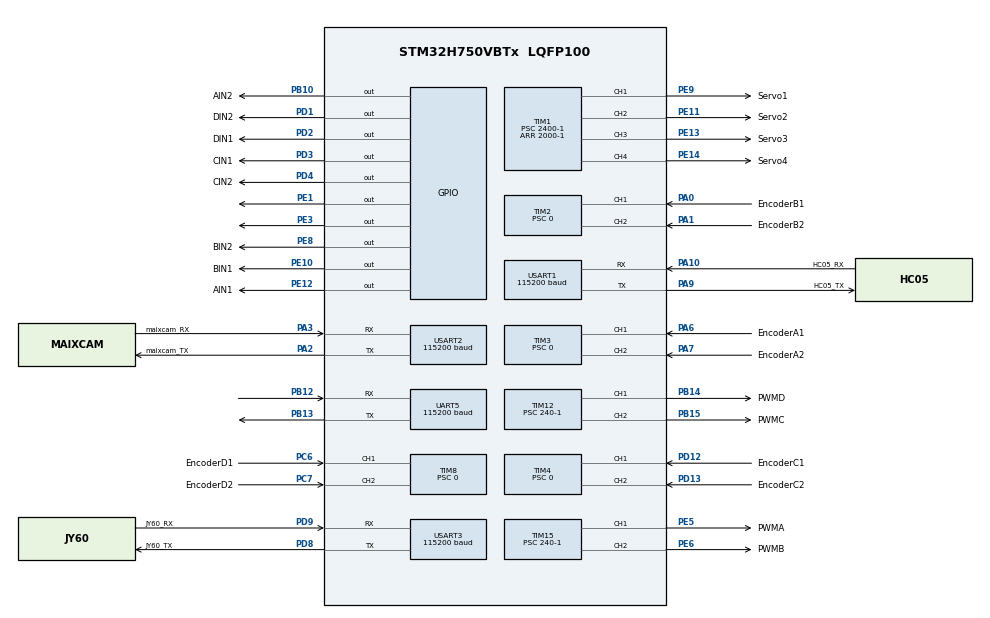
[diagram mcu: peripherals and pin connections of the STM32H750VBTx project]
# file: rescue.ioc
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CORTEX_M7.default_mode_Activation=1
Dma.Request0=USART2_RX
Dma.Request1=USART3_RX
Dma.Request2=UART5_RX
Dma.Request3=USART1_RX
Dma.Request4=USART1_TX
Dma.UART5_RX.2.Direction=DMA_PERIPH_TO_MEMORY
Dma.UART5_RX.2.EventEnable=DISABLE
Dma.UART5_RX.2.FIFOMode=DMA_FIFOMODE_DISABLE
Dma.UART5_RX.2.Instance=DMA1_Stream2
Dma.UART5_RX.2.MemDataAlignment=DMA_MDATAALIGN_BYTE
Dma.UART5_RX.2.MemInc=DMA_MINC_ENABLE
Dma.UART5_RX.2.Mode=DMA_NORMAL
Dma.UART5_RX.2.PeriphDataAlignment=DMA_PDATAALIGN_BYTE
Dma.UART5_RX.2.PeriphInc=DMA_PINC_DISABLE
Dma.UART5_RX.2.Polarity=HAL_DMAMUX_REQ_GEN_RISING
Dma.UART5_RX.2.Priority=DMA_PRIORITY_LOW
Dma.UART5_RX.2.RequestNumber=1
Dma.UART5_RX.2.SignalID=NONE
Dma.UART5_RX.2.SyncEnable=DISABLE
Dma.UART5_RX.2.SyncPolarity=HAL_DMAMUX_SYNC_NO_EVENT
Dma.UART5_RX.2.SyncRequestNumber=1
Dma.UART5_RX.2.SyncSignalID=NONE
Dma.USART1_RX.3.Direction=DMA_PERIPH_TO_MEMORY
Dma.USART1_RX.3.EventEnable=DISABLE
Dma.USART1_RX.3.FIFOMode=DMA_FIFOMODE_DISABLE
Dma.USART1_RX.3.Instance=DMA1_Stream3
Dma.USART1_RX.3.MemDataAlignment=DMA_MDATAALIGN_BYTE
Dma.USART1_RX.3.MemInc=DMA_MINC_ENABLE
Dma.USART1_RX.3.Mode=DMA_NORMAL
Dma.USART1_RX.3.PeriphDataAlignment=DMA_PDATAALIGN_BYTE
Dma.USART1_RX.3.PeriphInc=DMA_PINC_DISABLE
Dma.USART1_RX.3.Polarity=HAL_DMAMUX_REQ_GEN_RISING
Dma.USART1_RX.3.Priority=DMA_PRIORITY_LOW
Dma.USART1_RX.3.RequestNumber=1
Dma.USART1_RX.3.SignalID=NONE
Dma.USART1_RX.3.SyncEnable=DISABLE
Dma.USART1_RX.3.SyncPolarity=HAL_DMAMUX_SYNC_NO_EVENT
Dma.USART1_RX.3.SyncRequestNumber=1
Dma.USART1_RX.3.SyncSignalID=NONE
Dma.USART1_TX.4.Direction=DMA_MEMORY_TO_PERIPH
Dma.USART1_TX.4.EventEnable=DISABLE
Dma.USART1_TX.4.FIFOMode=DMA_FIFOMODE_DISABLE
Dma.USART1_TX.4.Instance=DMA1_Stream4
Dma.USART1_TX.4.MemDataAlignment=DMA_MDATAALIGN_BYTE
Dma.USART1_TX.4.MemInc=DMA_MINC_ENABLE
Dma.USART1_TX.4.Mode=DMA_NORMAL
Dma.USART1_TX.4.PeriphDataAlignment=DMA_PDATAALIGN_BYTE
Dma.USART1_TX.4.PeriphInc=DMA_PINC_DISABLE
Dma.USART1_TX.4.Polarity=HAL_DMAMUX_REQ_GEN_RISING
Dma.USART1_TX.4.Priority=DMA_PRIORITY_LOW
Dma.USART1_TX.4.RequestNumber=1
Dma.USART1_TX.4.SignalID=NONE
Dma.USART1_TX.4.SyncEnable=DISABLE
Dma.USART1_TX.4.SyncPolarity=HAL_DMAMUX_SYNC_NO_EVENT
Dma.USART1_TX.4.SyncRequestNumber=1
Dma.USART1_TX.4.SyncSignalID=NONE
Dma.USART2_RX.0.Direction=DMA_PERIPH_TO_MEMORY
Dma.USART2_RX.0.EventEnable=DISABLE
Dma.USART2_RX.0.FIFOMode=DMA_FIFOMODE_DISABLE
Dma.USART2_RX.0.Instance=DMA1_Stream0
Dma.USART2_RX.0.MemDataAlignment=DMA_MDATAALIGN_BYTE
Dma.USART2_RX.0.MemInc=DMA_MINC_ENABLE
Dma.USART2_RX.0.Mode=DMA_NORMAL
Dma.USART2_RX.0.PeriphDataAlignment=DMA_PDATAALIGN_BYTE
Dma.USART2_RX.0.PeriphInc=DMA_PINC_DISABLE
Dma.USART2_RX.0.Polarity=HAL_DMAMUX_REQ_GEN_RISING
Dma.USART2_RX.0.Priority=DMA_PRIORITY_LOW
Dma.USART2_RX.0.RequestNumber=1
Dma.USART2_RX.0.SignalID=NONE
Dma.USART2_RX.0.SyncEnable=DISABLE
Dma.USART2_RX.0.SyncPolarity=HAL_DMAMUX_SYNC_NO_EVENT
Dma.USART2_RX.0.SyncRequestNumber=1
Dma.USART2_RX.0.SyncSignalID=NONE
Dma.USART3_RX.1.Direction=DMA_PERIPH_TO_MEMORY
Dma.USART3_RX.1.EventEnable=DISABLE
Dma.USART3_RX.1.FIFOMode=DMA_FIFOMODE_DISABLE
Dma.USART3_RX.1.Instance=DMA1_Stream1
Dma.USART3_RX.1.MemDataAlignment=DMA_MDATAALIGN_BYTE
Dma.USART3_RX.1.MemInc=DMA_MINC_ENABLE
Dma.USART3_RX.1.Mode=DMA_NORMAL
Dma.USART3_RX.1.PeriphDataAlignment=DMA_PDATAALIGN_BYTE
Dma.USART3_RX.1.PeriphInc=DMA_PINC_DISABLE
Dma.USART3_RX.1.Polarity=HAL_DMAMUX_REQ_GEN_RISING
Dma.USART3_RX.1.Priority=DMA_PRIORITY_LOW
Dma.USART3_RX.1.RequestNumber=1
Dma.USART3_RX.1.SignalID=NONE
Dma.USART3_RX.1.SyncEnable=DISABLE
Dma.USART3_RX.1.SyncPolarity=HAL_DMAMUX_SYNC_NO_EVENT
Dma.USART3_RX.1.SyncRequestNumber=1
Dma.USART3_RX.1.SyncSignalID=NONE
FREERTOS.Tasks01=defaultTask,24,128,StartDefaultTask,Default,NULL,Dynamic,NULL,NULL
FREERTOS.configUSE_NEWLIB_REENTRANT=1
Mcu.Family=STM32H7
Mcu.Name=STM32H750VBTx
Mcu.Package=LQFP100
NVIC.DMA1_Stream0_IRQn=true\:5\:0\:false\:false\:true\:true\:false\:true\:true
NVIC.DMA1_Stream1_IRQn=true\:5\:0\:false\:false\:true\:true\:false\:true\:true
NVIC.DMA1_Stream2_IRQn=true\:5\:0\:false\:false\:true\:true\:false\:true\:true
NVIC.DMA1_Stream3_IRQn=true\:5\:0\:false\:false\:true\:true\:false\:true\:true
NVIC.DMA1_Stream4_IRQn=true\:5\:0\:false\:false\:true\:true\:false\:true\:true
NVIC.PriorityGroup=NVIC_PRIORITYGROUP_4
NVIC.TIM17_IRQn=true\:15\:0\:false\:false\:true\:false\:false\:true\:true
NVIC.TIM5_IRQn=true\:7\:0\:true\:false\:true\:true\:true\:true\:true
NVIC.TIM6_DAC_IRQn=true\:8\:0\:true\:false\:true\:true\:true\:true\:true
NVIC.TimeBase=TIM17_IRQn
NVIC.TimeBaseIP=TIM17
NVIC.UART5_IRQn=true\:7\:0\:true\:false\:true\:true\:true\:true\:true
NVIC.USART1_IRQn=true\:7\:0\:true\:false\:true\:true\:true\:true\:true
NVIC.USART2_IRQn=true\:7\:0\:true\:false\:true\:true\:true\:true\:true
NVIC.USART3_IRQn=true\:7\:0\:true\:false\:true\:true\:true\:true\:true
PA0.GPIO_Label=EncoderB1
PA0.GPIO_PuPd=GPIO_PULLUP
PA0.Signal=S_TIM2_CH1_ETR
PA1.GPIO_Label=EncoderB2
PA1.GPIO_PuPd=GPIO_PULLUP
PA1.Signal=S_TIM2_CH2
PA10.GPIO_Label=HC05_RX
PA10.Mode=Asynchronous
PA10.Signal=USART1_RX
PA2.GPIO_Label=maixcam_TX
PA2.Mode=Asynchronous
PA2.Signal=USART2_TX
PA3.GPIO_Label=maixcam_RX
PA3.Mode=Asynchronous
PA3.Signal=USART2_RX
PA6.GPIO_Label=EncoderA1
PA6.GPIO_PuPd=GPIO_PULLUP
PA6.Signal=S_TIM3_CH1
PA7.GPIO_Label=EncoderA2
PA7.GPIO_PuPd=GPIO_PULLUP
PA7.Signal=S_TIM3_CH2
PA9.GPIO_Label=HC05_TX
PA9.Mode=Asynchronous
PA9.Signal=USART1_TX
PB10.GPIO_Label=AIN2
PB10.Signal=GPIO_Output
PB12.Mode=Asynchronous
PB12.Signal=UART5_RX
PB13.Mode=Asynchronous
PB13.Signal=UART5_TX
PB14.GPIO_Label=PWMD
PB14.Signal=S_TIM12_CH1
PB15.GPIO_Label=PWMC
PB15.Signal=S_TIM12_CH2
PC6.GPIO_Label=EncoderD1
PC6.GPIO_PuPd=GPIO_PULLUP
PC6.Signal=S_TIM8_CH1
PC7.GPIO_Label=EncoderD2
PC7.GPIO_PuPd=GPIO_PULLUP
PC7.Signal=S_TIM8_CH2
PD1.GPIO_Label=DIN2
PD1.Signal=GPIO_Output
PD12.GPIO_Label=EncoderC1
PD12.GPIO_PuPd=GPIO_PULLUP
PD12.Signal=S_TIM4_CH1
PD13.GPIO_Label=EncoderC2
PD13.GPIO_PuPd=GPIO_PULLUP
PD13.Signal=S_TIM4_CH2
PD2.GPIO_Label=DIN1
PD2.Signal=GPIO_Output
PD3.GPIO_Label=CIN1
PD3.Signal=GPIO_Output
PD4.GPIO_Label=CIN2
PD4.Signal=GPIO_Output
PD8.GPIO_Label=JY60_TX
PD8.Mode=Asynchronous
PD8.Signal=USART3_TX
PD9.GPIO_Label=JY60_RX
PD9.Mode=Asynchronous
PD9.Signal=USART3_RX
PE1.Signal=GPIO_Output
PE10.GPIO_Label=BIN1
PE10.Signal=GPIO_Output
PE11.GPIO_Label=Servo2
PE11.Signal=S_TIM1_CH2
PE12.GPIO_Label=AIN1
PE12.Signal=GPIO_Output
PE13.GPIO_Label=Servo3
PE13.Signal=S_TIM1_CH3
PE14.GPIO_Label=Servo4
PE14.Signal=S_TIM1_CH4
PE3.GPIO_ModeDefaultOutputPP=GPIO_MODE_OUTPUT_OD
PE3.GPIO_PuPd=GPIO_PULLUP
PE3.PinState=GPIO_PIN_SET
PE3.Signal=GPIO_Output
PE5.GPIO_Label=PWMA
PE5.Signal=S_TIM15_CH1
PE6.GPIO_Label=PWMB
PE6.Signal=S_TIM15_CH2
PE8.GPIO_Label=BIN2
PE8.Signal=GPIO_Output
PE9.GPIO_Label=Servo1
PE9.Signal=S_TIM1_CH1
PH0-OSC_IN\ (PH0).Mode=HSE-External-Oscillator
PH0-OSC_IN\ (PH0).Signal=RCC_OSC_IN
PH1-OSC_OUT\ (PH1).Mode=HSE-External-Oscillator
PH1-OSC_OUT\ (PH1).Signal=RCC_OSC_OUT
ProjectManager.HeapSize=0x200
ProjectManager.StackSize=0x400
ProjectManager.TargetToolchain=STM32CubeIDE
RCC.ADCFreq_Value=129000000
RCC.APB1Freq_Value=120000000
RCC.APB2Freq_Value=120000000
RCC.APB3Freq_Value=120000000
RCC.APB4Freq_Value=120000000
RCC.CortexFreq_Value=480000000
RCC.D1PPRE=RCC_APB3_DIV2
RCC.D2PPRE1=RCC_APB1_DIV2
RCC.D2PPRE2=RCC_APB2_DIV2
RCC.D3PPRE=RCC_APB4_DIV2
RCC.DIVM1=4
RCC.DIVN1=60
RCC.DIVQ1=15
RCC.HCLKFreq_Value=240000000
RCC.HPRE=RCC_HCLK_DIV2
RCC.HSE_VALUE=4000000
RCC.PLL2FRACN=0
RCC.PLL3FRACN=0
RCC.PLLFRACN=0
RCC.SYSCLKFreq_VALUE=480000000
RCC.SYSCLKSource=RCC_SYSCLKSOURCE_PLLCLK
RCC.USBCLockSelection=RCC_USBCLKSOURCE_HSI48
RCC.USBFreq_Value=48000000
SH.S_TIM12_CH1.0=TIM12_CH1,PWM Generation1 CH1
SH.S_TIM12_CH2.0=TIM12_CH2,PWM Generation2 CH2
SH.S_TIM15_CH1.0=TIM15_CH1,PWM Generation1 CH1
SH.S_TIM15_CH2.0=TIM15_CH2,PWM Generation2 CH2
SH.S_TIM1_CH1.0=TIM1_CH1,PWM Generation1 CH1
SH.S_TIM1_CH2.0=TIM1_CH2,PWM Generation2 CH2
SH.S_TIM1_CH3.0=TIM1_CH3,PWM Generation3 CH3
SH.S_TIM1_CH4.0=TIM1_CH4,PWM Generation4 CH4
SH.S_TIM2_CH1_ETR.0=TIM2_CH1,Encoder_Interface
SH.S_TIM2_CH2.0=TIM2_CH2,Encoder_Interface
SH.S_TIM3_CH1.0=TIM3_CH1,Encoder_Interface
SH.S_TIM3_CH2.0=TIM3_CH2,Encoder_Interface
SH.S_TIM4_CH1.0=TIM4_CH1,Encoder_Interface
SH.S_TIM4_CH2.0=TIM4_CH2,Encoder_Interface
SH.S_TIM8_CH1.0=TIM8_CH1,Encoder_Interface
SH.S_TIM8_CH2.0=TIM8_CH2,Encoder_Interface
TIM1.Channel-PWM\ Generation1\ CH1=TIM_CHANNEL_1
TIM1.Channel-PWM\ Generation2\ CH2=TIM_CHANNEL_2
TIM1.Channel-PWM\ Generation3\ CH3=TIM_CHANNEL_3
TIM1.Channel-PWM\ Generation4\ CH4=TIM_CHANNEL_4
TIM1.Period=2000-1
TIM1.Prescaler=2400-1
TIM1.Pulse-PWM\ Generation1\ CH1=1500
TIM1.Pulse-PWM\ Generation2\ CH2=1500
TIM1.Pulse-PWM\ Generation3\ CH3=0
TIM12.Channel-PWM\ Generation1\ CH1=TIM_CHANNEL_1
TIM12.Channel-PWM\ Generation2\ CH2=TIM_CHANNEL_2
TIM12.Period=1000-1
TIM12.Prescaler=240-1
TIM15.Channel-PWM\ Generation1\ CH1=TIM_CHANNEL_1
TIM15.Channel-PWM\ Generation2\ CH2=TIM_CHANNEL_2
TIM15.Period=1000-1
TIM15.Prescaler=240-1
TIM15.Pulse-PWM\ Generation1\ CH1=100
TIM2.EncoderMode=TIM_ENCODERMODE_TI12
TIM2.IC1Filter=10
TIM2.IC2Filter=10
TIM2.Prescaler=0
TIM3.EncoderMode=TIM_ENCODERMODE_TI12
TIM3.IC1Filter=10
TIM3.IC2Filter=10
TIM3.Prescaler=0
TIM4.EncoderMode=TIM_ENCODERMODE_TI12
TIM4.IC1Filter=10
TIM4.IC2Filter=10
TIM4.Prescaler=0
TIM5.AutoReloadPreload=TIM_AUTORELOAD_PRELOAD_ENABLE
TIM5.Period=1250-1
TIM5.Prescaler=24000-1
TIM6.Period=2400-1
TIM6.Prescaler=1000-1
TIM8.EncoderMode=TIM_ENCODERMODE_TI12
TIM8.IC1Filter=10
TIM8.IC2Filter=10
TIM8.Prescaler=0
UART5.BaudRate=115200
USART1.BaudRate=115200
USART1.VirtualMode-Asynchronous=VM_ASYNC
USART2.BaudRate=115200
USART2.VirtualMode-Asynchronous=VM_ASYNC
USART3.BaudRate=115200
USART3.VirtualMode-Asynchronous=VM_ASYNC
VP_FREERTOS_VS_CMSIS_V2.Mode=CMSIS_V2
VP_MEMORYMAP_VS_MEMORYMAP.Mode=CurAppReg
VP_SYS_VS_tim17.Mode=TIM17
VP_TIM12_VS_ClockSourceINT.Mode=Internal
VP_TIM15_VS_ClockSourceINT.Mode=Internal
VP_TIM5_VS_ClockSourceINT.Mode=Internal
VP_TIM6_VS_ClockSourceINT.Mode=Enable_Timer
board=custom

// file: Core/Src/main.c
/* USER CODE BEGIN Header */
/**
  ******************************************************************************
  * @file           : main.c
  * @brief          : Main program body
  ******************************************************************************
  * @attention
  *
  * Copyright (c) 2026 STMicroelectronics.
  * All rights reserved.
  *
  * This software is licensed under terms that can be found in the LICENSE file
  * in the root directory of this software component.
  * If no LICENSE file comes with this software, it is provided AS-IS.
  *
  ******************************************************************************
  */
/* USER CODE END Header */
#include "main.h"
#include "FreeRTOS.h"
#include "cmsis_os2.h"
#include "dma.h"
#include "tim.h"
#include "usart.h"
#include "gpio.h"

void SystemClock_Config(void);
static void MPU_Config(void);
void MX_FREERTOS_Init(void);

int main(void)
{

  /* MPU Configuration--------------------------------------------------------*/
  MPU_Config();

  /* MCU Configuration--------------------------------------------------------*/

  /* Reset of all peripherals, Initializes the Flash interface and the Systick. */
  HAL_Init();

  /* Configure the system clock */
  SystemClock_Config();

  /* Initialize all configured peripherals */
  MX_GPIO_Init();
  MX_DMA_Init();
  MX_TIM1_Init();
  MX_TIM2_Init();
  MX_TIM3_Init();
  MX_TIM4_Init();
  MX_TIM8_Init();
  MX_TIM12_Init();
  MX_TIM15_Init();
  MX_USART1_UART_Init();
  MX_USART2_UART_Init();
  MX_USART3_UART_Init();
  MX_TIM5_Init();
  MX_TIM6_Init();
  MX_UART5_Init();

  /* Init scheduler */
  osKernelInitialize();  /* Call init function for freertos objects (in cmsis_os2.c) */
  MX_FREERTOS_Init();

  /* Start scheduler */
  osKernelStart();

  /* We should never get here as control is now taken by the scheduler */

  /* Infinite loop */
  while (1)
  {
  }
}

void SystemClock_Config(void)
{
  RCC_OscInitTypeDef RCC_OscInitStruct = {0};
  RCC_ClkInitTypeDef RCC_ClkInitStruct = {0};

  /** Supply configuration update enable
  */
  HAL_PWREx_ConfigSupply(PWR_LDO_SUPPLY);

  /** Configure the main internal regulator output voltage
  */
  __HAL_PWR_VOLTAGESCALING_CONFIG(PWR_REGULATOR_VOLTAGE_SCALE0);

  while(!__HAL_PWR_GET_FLAG(PWR_FLAG_VOSRDY)) {}

  /** Initializes the RCC Oscillators according to the specified parameters
  * in the RCC_OscInitTypeDef structure.
  */
  RCC_OscInitStruct.OscillatorType = RCC_OSCILLATORTYPE_HSI;
  RCC_OscInitStruct.HSIState = RCC_HSI_DIV1;
  RCC_OscInitStruct.HSICalibrationValue = RCC_HSICALIBRATION_DEFAULT;
  RCC_OscInitStruct.PLL.PLLState = RCC_PLL_ON;
  RCC_OscInitStruct.PLL.PLLSource = RCC_PLLSOURCE_HSI;
  RCC_OscInitStruct.PLL.PLLM = 4;
  RCC_OscInitStruct.PLL.PLLN = 60;
  RCC_OscInitStruct.PLL.PLLP = 2;
  RCC_OscInitStruct.PLL.PLLQ = 15;
  RCC_OscInitStruct.PLL.PLLR = 2;
  RCC_OscInitStruct.PLL.PLLRGE = RCC_PLL1VCIRANGE_3;
  RCC_OscInitStruct.PLL.PLLVCOSEL = RCC_PLL1VCOWIDE;
  RCC_OscInitStruct.PLL.PLLFRACN = 0;
  if (HAL_RCC_OscConfig(&RCC_OscInitStruct) != HAL_OK)
  {
    Error_Handler();
  }

  /** Initializes the CPU, AHB and APB buses clocks
  */
  RCC_ClkInitStruct.ClockType = RCC_CLOCKTYPE_HCLK|RCC_CLOCKTYPE_SYSCLK
                              |RCC_CLOCKTYPE_PCLK1|RCC_CLOCKTYPE_PCLK2
                              |RCC_CLOCKTYPE_D3PCLK1|RCC_CLOCKTYPE_D1PCLK1;
  RCC_ClkInitStruct.SYSCLKSource = RCC_SYSCLKSOURCE_PLLCLK;
  RCC_ClkInitStruct.SYSCLKDivider = RCC_SYSCLK_DIV1;
  RCC_ClkInitStruct.AHBCLKDivider = RCC_HCLK_DIV2;
  RCC_ClkInitStruct.APB3CLKDivider = RCC_APB3_DIV2;
  RCC_ClkInitStruct.APB1CLKDivider = RCC_APB1_DIV2;
  RCC_ClkInitStruct.APB2CLKDivider = RCC_APB2_DIV2;
  RCC_ClkInitStruct.APB4CLKDivider = RCC_APB4_DIV2;

  if (HAL_RCC_ClockConfig(&RCC_ClkInitStruct, FLASH_LATENCY_4) != HAL_OK)
  {
    Error_Handler();
  }
}

 /* MPU Configuration */

void MPU_Config(void)
{
  MPU_Region_InitTypeDef MPU_InitStruct = {0};

  /* Disables the MPU */
  HAL_MPU_Disable();

  /** Initializes and configures the Region and the memory to be protected
  */
  MPU_InitStruct.Enable = MPU_REGION_ENABLE;
  MPU_InitStruct.Number = MPU_REGION_NUMBER0;
  MPU_InitStruct.BaseAddress = 0x0;
  MPU_InitStruct.Size = MPU_REGION_SIZE_4GB;
  MPU_InitStruct.SubRegionDisable = 0x87;
  MPU_InitStruct.TypeExtField = MPU_TEX_LEVEL0;
  MPU_InitStruct.AccessPermission = MPU_REGION_NO_ACCESS;
  MPU_InitStruct.DisableExec = MPU_INSTRUCTION_ACCESS_DISABLE;
  MPU_InitStruct.IsShareable = MPU_ACCESS_SHAREABLE;
  MPU_InitStruct.IsCacheable = MPU_ACCESS_NOT_CACHEABLE;
  MPU_InitStruct.IsBufferable = MPU_ACCESS_NOT_BUFFERABLE;

  HAL_MPU_ConfigRegion(&MPU_InitStruct);
  /* Enables the MPU */
  HAL_MPU_Enable(MPU_PRIVILEGED_DEFAULT);

}

void HAL_TIM_PeriodElapsedCallback(TIM_HandleTypeDef *htim)
{
  if (htim->Instance == TIM17)
  {
    HAL_IncTick();
  }
}

void Error_Handler(void)
{
  __disable_irq();
  while (1)
  {
  }
}

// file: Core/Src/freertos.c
/* USER CODE BEGIN Header */
/**
  ******************************************************************************
  * File Name          : freertos.c
  * Description        : Code for freertos applications
  ******************************************************************************
  * @attention
  *
  * Copyright (c) 2026 STMicroelectronics.
  * All rights reserved.
  *
  * This software is licensed under terms that can be found in the LICENSE file
  * in the root directory of this software component.
  * If no LICENSE file comes with this software, it is provided AS-IS.
  *
  ******************************************************************************
  */
/* USER CODE END Header */

#include "FreeRTOS.h"
#include "task.h"
#include "main.h"
#include "FreeRTOS.h"
#include "cmsis_os2.h"

/* USER CODE BEGIN Includes */
#include "car_task.h"
/* USER CODE END Includes */

/* Definitions for defaultTask */
osThreadId_t defaultTaskHandle;
const osThreadAttr_t defaultTask_attributes = {
  .name = "defaultTask",
  .stack_size = 128 * 4,
  .priority = (osPriority_t) osPriorityNormal,
};

void StartDefaultTask(void *argument);

void MX_FREERTOS_Init(void); /* (MISRA C 2004 rule 8.1) */

void MX_FREERTOS_Init(void) {
  /* USER CODE BEGIN Init */
  Start_task_create();
  /* USER CODE END Init */

  /* Create the thread(s) */
  /* creation of defaultTask */
  defaultTaskHandle = osThreadNew(StartDefaultTask, NULL, &defaultTask_attributes);

}

void StartDefaultTask(void *argument)
{
  for(;;)
  {
    osDelay(1);
  }
}
